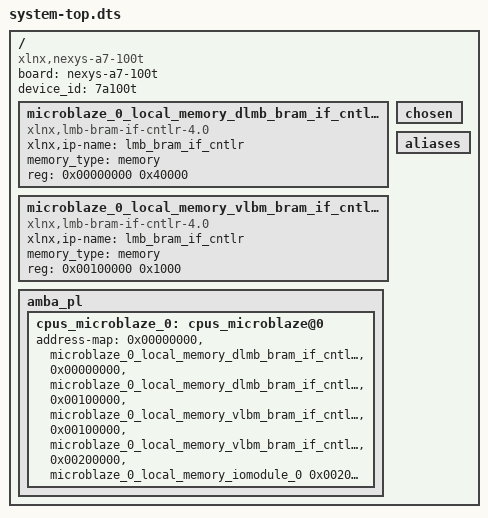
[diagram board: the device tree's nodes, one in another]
/dts-v1/;
#include "pl.dtsi"
/ {
	board = "nexys-a7-100t";
	compatible = "xlnx,nexys-a7-100t";
	device_id = "7a100t";
	#address-cells = <1>;
	#size-cells = <1>;
	microblaze_0_local_memory_dlmb_bram_if_cntlr_memory: memory@0 {
		compatible = "xlnx,lmb-bram-if-cntlr-4.0";
		xlnx,ip-name = "lmb_bram_if_cntlr";
		device_type = "memory";
		memory_type = "memory";
		reg = <0x00000000 0x40000>;
	};
	microblaze_0_local_memory_vlbm_bram_if_cntlr_memory: memory@100000 {
		compatible = "xlnx,lmb-bram-if-cntlr-4.0";
		xlnx,ip-name = "lmb_bram_if_cntlr";
		device_type = "memory";
		memory_type = "memory";
		reg = <0x00100000 0x1000>;
	};
	chosen {
	};
	aliases {
	};
	amba_pl: amba_pl {
		cpus_microblaze_0: cpus_microblaze@0 {
			address-map = <0x00000000 &microblaze_0_local_memory_dlmb_bram_if_cntlr_memory 0x00000000 0x40000>, 
			      <0x00000000 &microblaze_0_local_memory_dlmb_bram_if_cntlr 0x00000000 0x40000>, 
			      <0x00100000 &microblaze_0_local_memory_vlbm_bram_if_cntlr_memory 0x00100000 0x1000>, 
			      <0x00100000 &microblaze_0_local_memory_vlbm_bram_if_cntlr 0x00100000 0x1000>, 
			      <0x00200000 &microblaze_0_local_memory_iomodule_0 0x00200000 0x1000>;
			#ranges-address-cells = <0x1>;
			#ranges-size-cells = <0x1>;
		};
	};
};
